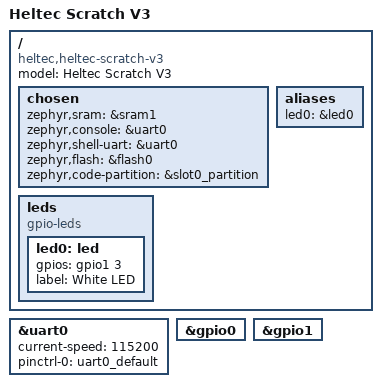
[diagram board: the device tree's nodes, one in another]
/dts-v1/;

#include <espressif/esp32s3/esp32s3_fn8.dtsi>
#include <espressif/partitions_0x0_amp.dtsi>
#include "heltec_scratch_v3-pinctrl.dtsi"
#include <zephyr/dt-bindings/gpio/gpio.h>

/{
    model = "Heltec Scratch V3";
    compatible = "heltec,heltec-scratch-v3";

    chosen {
        zephyr,sram = &sram1;
        zephyr,console = &uart0;
        zephyr,shell-uart = &uart0;
        zephyr,flash = &flash0;
        zephyr,code-partition = &slot0_partition;
    };

    aliases {
        led0 = &led0;
    };

    leds {
        compatible = "gpio-leds";
        led0: led {
            gpios = <&gpio1 3 GPIO_ACTIVE_HIGH>;
            label = "White LED";
        };
    };
};

&uart0 {
    status = "okay";
    current-speed = <115200>;
    pinctrl-0 = <&uart0_default>;
    pinctrl-names = "default";
};

&gpio0 {
    status = "okay";
};

&gpio1 {
    status = "okay";
};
